# LPC54S018M register map
Vendor: nxp.com; File version: 1.0
CPU: CM4 r0p1, little endian, MPU, FPU, VTOR, 3 interrupt priority bits
Registers are 32-bit, read-write, reset 0x0 unless marked. A register's access mark holds for its fields unless they carry their own. Offsets are from the block's base; [hi:lo] are bit positions.

## USBHSH — LPC54S60x/LPC5460x USB1 High-speed Host Controller
Base 0x400A3000
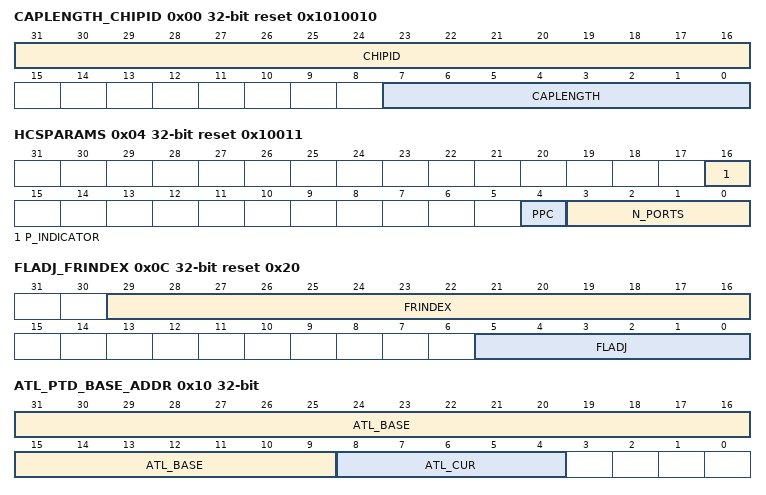
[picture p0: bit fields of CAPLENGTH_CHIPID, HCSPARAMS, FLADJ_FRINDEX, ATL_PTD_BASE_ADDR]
0x00 CAPLENGTH_CHIPID ro reset 0x1010010 — This register contains the offset value towards the start of the operational register space and the version number of the IP block
  [31:16] CHIPID — Chip identification: indicates major and minor revision of the IP: [31:24] = Major revision [23:16] = Minor revision Major revisions used: 0x01: USB2.
  [7:0] CAPLENGTH — Capability Length: This is used as an offset.
0x04 HCSPARAMS ro reset 0x10011 — Host Controller Structural Parameters
  [16] P_INDICATOR — This bit indicates whether the ports support port indicator control.
  [4] PPC — This field indicates whether the host controller implementation includes port power control.
  [3:0] N_PORTS — This register specifies the number of physical downstream ports implemented on this host controller.
0x08 HCCPARAMS ro reset 0x20006 — Host Controller Capability Parameters
  [17] LPMC — Link Power Management Capability.
0x0C FLADJ_FRINDEX reset 0x20 — Frame Length Adjustment
  [29:16] FRINDEX — Frame Index: Bits 29 to16 in this register are used for the frame number field in the SOF packet.
  [5:0] FLADJ — Frame Length Timing Value.
0x10 ATL_PTD_BASE_ADDR — Memory base address where ATL PTD0 is stored
  [31:9] ATL_BASE — Base address to be used by the hardware to find the start of the ATL list.
  [8:4] ATL_CUR — This indicates the current PTD that is used by the hardware when it is processing the ATL list.
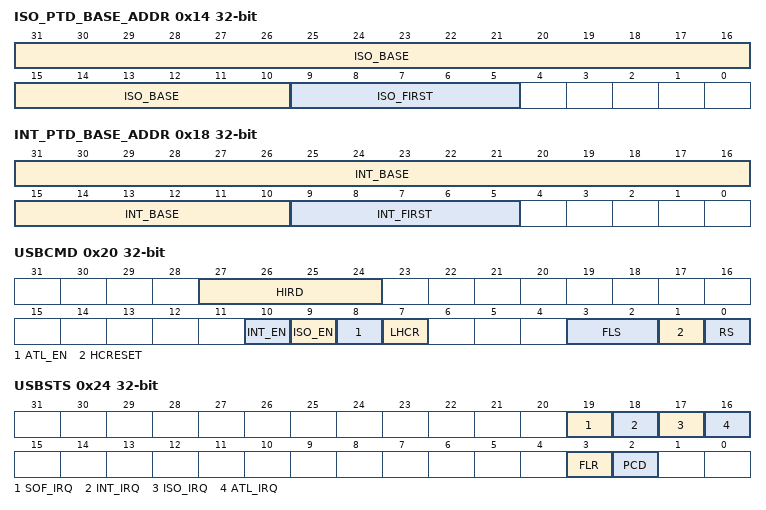
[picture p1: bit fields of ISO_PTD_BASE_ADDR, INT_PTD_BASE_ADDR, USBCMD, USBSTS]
0x14 ISO_PTD_BASE_ADDR — Memory base address where ISO PTD0 is stored
  [31:10] ISO_BASE — Base address to be used by the hardware to find the start of the ISO list.
  [9:5] ISO_FIRST — This indicates the first PTD that is used by the hardware when it is processing the ISO list.
0x18 INT_PTD_BASE_ADDR — Memory base address where INT PTD0 is stored
  [31:10] INT_BASE — Base address to be used by the hardware to find the start of the INT list.
  [9:5] INT_FIRST — This indicates the first PTD that is used by the hardware when it is processing the INT list.
0x1C DATA_PAYLOAD_BASE_ADDR — Memory base address that indicates the start of the data payload buffers
  [31:16] DAT_BASE — Base address to be used by the hardware to find the start of the data payload section.
0x20 USBCMD — USB Command register
  [27:24] HIRD — Host-Initiated Resume Duration.
  [10] INT_EN — INT List enabled.
  [9] ISO_EN — ISO List enabled.
  [8] ATL_EN — ATL List enabled.
  [7] LHCR — Light Host Controller Reset: This bit allows the driver software to reset the host controller without affecting the state of the ports.
  [3:2] FLS — Frame List Size: This field specifies the size of the frame list.
  [1] HCRESET — Host Controller Reset: This control bit is used by the software to reset the host controller.
  [0] RS — Run/Stop: 1b = Run.
0x24 USBSTS — USB Interrupt Status register
  [19] SOF_IRQ — SOF interrupt: Every time when the host sends a Start of Frame token on the USB bus, this bit is set.
  [18] INT_IRQ — INT IRQ: Indicates that an INT PTD (with I-bit set) was completed.
  [17] ISO_IRQ — ISO IRQ: Indicates that an ISO PTD (with I-bit set) was completed.
  [16] ATL_IRQ — ATL IRQ: Indicates that an ATL PTD (with I-bit set) was completed.
  [3] FLR — Frame List Rollover: The host controller sets this bit to logic 1 when the frame list index rolls over its maximum value to 0.
  [2] PCD — Port Change Detect: The host controller sets this bit to logic 1 when any port has a change bit transition from a 0 to a one or a Force Port Resume bit transition from a 0 to a 1 as a result of a J-K transition detected on a suspended port.
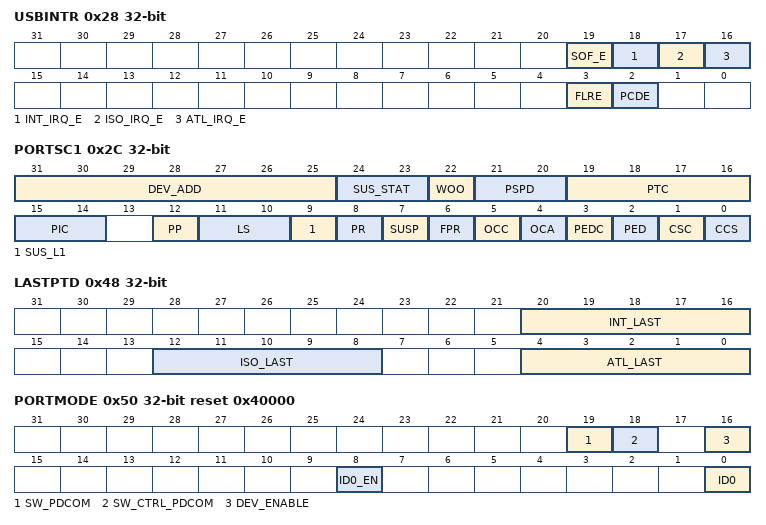
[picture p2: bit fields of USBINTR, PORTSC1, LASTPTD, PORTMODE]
0x28 USBINTR — USB Interrupt Enable register
  [19] SOF_E — SOF Interrupt Enable bit: 1: enable 0: disable.
  [18] INT_IRQ_E — INT IRQ Enable bit: 1: enable 0: disable.
  [17] ISO_IRQ_E — ISO IRQ Enable bit: 1: enable 0: disable.
  [16] ATL_IRQ_E — ATL IRQ Enable bit: 1: enable 0: disable.
  [3] FLRE — Frame List Rollover Interrupt Enable: 1: enable 0: disable.
  [2] PCDE — Port Change Detect Interrupt Enable: 1: enable 0: disable.
0x2C PORTSC1 — Port Status and Control register
  [31:25] DEV_ADD — Device Address for LPM tokens.
  [24:23] SUS_STAT — These two bits are used by software to determine whether the most recent L1 suspend request was successful: 00b: Success-state transition was successful (ACK) 01b: Not Yet - Device was unable to enter the L1 state at this time (NYET) 10b: Not supported - Device does not support the L1 state (STALL) 11b: Timeout/Error - Device failed to respond or an error occurred.
  [22] WOO — Wake on overcurrent enable: Writing this bit to a one enables the port to be sensitive to overcurrent conditions as wake-up events.
  [21:20] PSPD — Port Speed: 00b: Low-speed 01b: Full-speed 10b: High-speed 11b: Reserved.
  [19:16] PTC — Port Test Control: A non-zero value indicates that the port is operating in the test mode as indicated by the value.
  [15:14] PIC — Port Indicator Control : Writing to this field has no effect if the P_INDICATOR bit in the HCSPARAMS register is logic 0.
  [12] PP — Port Power: The function of this bit depends on the value of the Port Power Control (PPC) bit in the HCSPARAMS register.
  [11:10] LS ro — Line Status: This field reflects the current logical levels of the DP (bit 11) and DM (bit 10) signal lines.
  [9] SUS_L1 — Suspend using L1 0b = Suspend using L2 1b = Suspend using L1 When this bit is set to a 1 and a non-zero value is specified in the Device Address field, the host controller will generate an LPM Token to enter the L1 state whenever software writes a one to the Suspend bit, as well as L1 exit timing during any device or host-initiated resume.
  [8] PR — Port Reset: Logic 1 means the port is in the reset state.
  [7] SUSP — Suspend: Logic 1 means port is in the suspend state.
  [6] FPR — Force Port Resume: Logic 1 means resume (K-state) detected or driven on the port.
  [5] OCC — Over-current change: Logic 1 means that the value of OCA has changed.
  [4] OCA — Over-current active: Logic 1 means that this port has an over-current condition.
  [3] PEDC — Port Enabled/Disabled Change: Logic 1 means that the value of PED has changed.
  [2] PED — Port Enabled/Disabled.
  [1] CSC — Connect Status Change: Logic 1 means that the value of CCS has changed.
  [0] CCS — Current Connect Status: Logic 1 indicates a device is present on the port.
0x30 ATL_PTD_DONE_MAP — Done map for each ATL PTD
  [31:0] ATL_DONE — The bit corresponding to a certain PTD will be set to logic 1 as soon as that PTD execution is completed.
0x34 ATL_PTD_SKIP_MAP — Skip map for each ATL PTD
  [31:0] ATL_SKIP — When a bit in the PTD Skip Map is set to logic 1, the corresponding PTD will be skipped, independent of the V bit setting.
0x38 ISO_PTD_DONE_MAP — Done map for each ISO PTD
  [31:0] ISO_DONE — The bit corresponding to a certain PTD will be set to logic 1 as soon as that PTD execution is completed.
0x3C ISO_PTD_SKIP_MAP — Skip map for each ISO PTD
  [31:0] ISO_SKIP — The bit corresponding to a certain PTD will be set to logic 1 as soon as that PTD execution is completed.
0x40 INT_PTD_DONE_MAP — Done map for each INT PTD
  [31:0] INT_DONE — The bit corresponding to a certain PTD will be set to logic 1 as soon as that PTD execution is completed.
0x44 INT_PTD_SKIP_MAP — Skip map for each INT PTD
  [31:0] INT_SKIP — When a bit in the PTD Skip Map is set to logic 1, the corresponding PTD will be skipped, independent of the V bit setting.
0x48 LASTPTD — Marks the last PTD in the list for ISO, INT and ATL
  [20:16] INT_LAST — This indicates the last PTD in the INT list.
  [12:8] ISO_LAST — This indicates the last PTD in the ISO list.
  [4:0] ATL_LAST — If hardware has reached this PTD and the J bit is not set, it will go to PTD0 as the next PTD to be processed.
0x50 PORTMODE reset 0x40000 — Controls the port if it is attached to the host block or the device block
  [19] SW_PDCOM — This bit is only used when SW_CTRL_PDCOM is set to 1b.
  [18] SW_CTRL_PDCOM — This bit indicates if the PHY power-down input is controlled by software or by hardware.
  [16] DEV_ENABLE — If this bit is set to one, one of the ports will behave as a USB device.
  [8] ID0_EN — Port 0 ID pin pull-up enable.
  [0] ID0 — Port 0 ID pin value.
